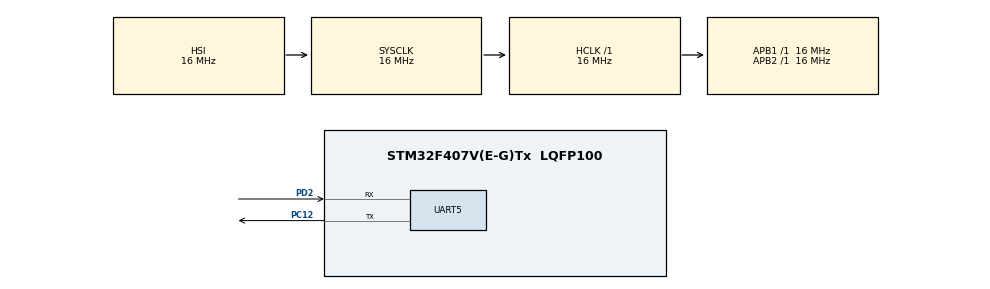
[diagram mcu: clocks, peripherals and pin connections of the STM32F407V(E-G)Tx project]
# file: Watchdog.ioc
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IWDG.Prescaler=IWDG_PRESCALER_32
IWDG.Reload=999
Mcu.Family=STM32F4
Mcu.Name=STM32F407V(E-G)Tx
Mcu.Package=LQFP100
NVIC.PriorityGroup=NVIC_PRIORITYGROUP_4
PA13.Mode=Serial_Wire
PA13.Signal=SYS_JTMS-SWDIO
PA14.Mode=Serial_Wire
PA14.Signal=SYS_JTCK-SWCLK
PC12.Mode=Asynchronous
PC12.Signal=UART5_TX
PD2.Mode=Asynchronous
PD2.Signal=UART5_RX
ProjectManager.HeapSize=0x200
ProjectManager.StackSize=0x400
ProjectManager.TargetToolchain=MDK-ARM V5.32
RCC.AHBFreq_Value=16000000
RCC.APB1Freq_Value=16000000
RCC.APB2Freq_Value=16000000
RCC.CortexFreq_Value=16000000
RCC.HSE_VALUE=25000000
RCC.HSI_VALUE=16000000
RCC.LSE_VALUE=32768
RCC.SYSCLKFreq_VALUE=16000000
RCC.VCOOutputFreq_Value=192000000
UART5.VirtualMode=Asynchronous
VP_IWDG_VS_IWDG.Mode=IWDG_Activate
board=custom

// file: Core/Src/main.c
/* USER CODE BEGIN Header */
/**
  ******************************************************************************
  * @file           : main.c
  * @brief          : Main program body
  ******************************************************************************
  * @attention
  *
  * Copyright (c) 2026 STMicroelectronics.
  * All rights reserved.
  *
  * This software is licensed under terms that can be found in the LICENSE file
  * in the root directory of this software component.
  * If no LICENSE file comes with this software, it is provided AS-IS.
  *
  ******************************************************************************
  */
/* USER CODE END Header */
#include "main.h"

/* USER CODE BEGIN Includes */
#include "stdio.h"
#include "string.h"
/* USER CODE END Includes */

IWDG_HandleTypeDef hiwdg;

UART_HandleTypeDef huart5;

void SystemClock_Config(void);
static void MX_GPIO_Init(void);
static void MX_IWDG_Init(void);
static void MX_UART5_Init(void);

int main(void)
{

  /* MCU Configuration--------------------------------------------------------*/

  /* Reset of all peripherals, Initializes the Flash interface and the Systick. */
  HAL_Init();

  /* Configure the system clock */
  SystemClock_Config();

  /* Initialize all configured peripherals */
  MX_GPIO_Init();
  MX_IWDG_Init();
  MX_UART5_Init();

  /* Infinite loop */
  /* USER CODE BEGIN WHILE */
	char start[] = "Start!\r\n";
	char refresh[] = "Refreshes IWDG!\r\n";

	HAL_UART_Transmit(&huart5, (uint8_t *)start, strlen(start), 10);
  while (1)
  {
    /* USER CODE END WHILE */

    /* USER CODE BEGIN 3 */
    HAL_UART_Transmit(&huart5, (uint8_t *)refresh, strlen(refresh), 10);

    HAL_IWDG_Refresh(&hiwdg);

		HAL_Delay(800);
  }
  /* USER CODE END 3 */
}

void SystemClock_Config(void)
{
  RCC_OscInitTypeDef RCC_OscInitStruct = {0};
  RCC_ClkInitTypeDef RCC_ClkInitStruct = {0};

  /** Configure the main internal regulator output voltage
  */
  __HAL_RCC_PWR_CLK_ENABLE();
  __HAL_PWR_VOLTAGESCALING_CONFIG(PWR_REGULATOR_VOLTAGE_SCALE1);

  /** Initializes the RCC Oscillators according to the specified parameters
  * in the RCC_OscInitTypeDef structure.
  */
  RCC_OscInitStruct.OscillatorType = RCC_OSCILLATORTYPE_HSI|RCC_OSCILLATORTYPE_LSI;
  RCC_OscInitStruct.HSIState = RCC_HSI_ON;
  RCC_OscInitStruct.HSICalibrationValue = RCC_HSICALIBRATION_DEFAULT;
  RCC_OscInitStruct.LSIState = RCC_LSI_ON;
  RCC_OscInitStruct.PLL.PLLState = RCC_PLL_NONE;
  if (HAL_RCC_OscConfig(&RCC_OscInitStruct) != HAL_OK)
  {
    Error_Handler();
  }

  /** Initializes the CPU, AHB and APB buses clocks
  */
  RCC_ClkInitStruct.ClockType = RCC_CLOCKTYPE_HCLK|RCC_CLOCKTYPE_SYSCLK
                              |RCC_CLOCKTYPE_PCLK1|RCC_CLOCKTYPE_PCLK2;
  RCC_ClkInitStruct.SYSCLKSource = RCC_SYSCLKSOURCE_HSI;
  RCC_ClkInitStruct.AHBCLKDivider = RCC_SYSCLK_DIV1;
  RCC_ClkInitStruct.APB1CLKDivider = RCC_HCLK_DIV1;
  RCC_ClkInitStruct.APB2CLKDivider = RCC_HCLK_DIV1;

  if (HAL_RCC_ClockConfig(&RCC_ClkInitStruct, FLASH_LATENCY_0) != HAL_OK)
  {
    Error_Handler();
  }
}

static void MX_IWDG_Init(void)
{

  hiwdg.Instance = IWDG;
  hiwdg.Init.Prescaler = IWDG_PRESCALER_32;
  hiwdg.Init.Reload = 999;
  if (HAL_IWDG_Init(&hiwdg) != HAL_OK)
  {
    Error_Handler();
  }

}

static void MX_UART5_Init(void)
{

  huart5.Instance = UART5;
  huart5.Init.BaudRate = 115200;
  huart5.Init.WordLength = UART_WORDLENGTH_8B;
  huart5.Init.StopBits = UART_STOPBITS_1;
  huart5.Init.Parity = UART_PARITY_NONE;
  huart5.Init.Mode = UART_MODE_TX_RX;
  huart5.Init.HwFlowCtl = UART_HWCONTROL_NONE;
  huart5.Init.OverSampling = UART_OVERSAMPLING_16;
  if (HAL_UART_Init(&huart5) != HAL_OK)
  {
    Error_Handler();
  }

}

static void MX_GPIO_Init(void)
{

  /* GPIO Ports Clock Enable */
  __HAL_RCC_GPIOA_CLK_ENABLE();
  __HAL_RCC_GPIOC_CLK_ENABLE();
  __HAL_RCC_GPIOD_CLK_ENABLE();

}

void Error_Handler(void)
{
  __disable_irq();
  while (1)
  {
  }
}
